VERSION ""

NS_ :

BU_: EBCM EON CAM RADAR PCM EPS VSA SCM BDY XXX EPB

BO_ 506 BRAKE_COMMAND: 8 ADAS
 SG_ COMPUTER_BRAKE : 7|10@0+ (1,0) [0|1] "" EBCM
 SG_ SET_ME_X00 : 13|5@0+ (1,0) [0|1] "" EBCM
 SG_ BRAKE_PUMP_REQUEST : 8|1@0+ (1,0) [0|1] "" EBCM
 SG_ SET_ME_X00_2 : 23|3@0+ (1,0) [0|1] "" EBCM
 SG_ CRUISE_OVERRIDE : 20|1@0+ (1,0) [0|1] "" EBCM
 SG_ SET_ME_X00_3 : 19|1@0+ (1,0) [0|1] "" EBCM
 SG_ CRUISE_FAULT_CMD : 18|1@0+ (1,0) [0|1] "" EBCM
 SG_ CRUISE_CANCEL_CMD : 17|1@0+ (1,0) [0|1] "" EBCM
 SG_ COMPUTER_BRAKE_REQUEST : 16|1@0+ (1,0) [0|1] "" EBCM
 SG_ SET_ME_1 : 31|1@0+ (1,0) [0|1] "" EBCM
 SG_ AEB_REQ_1 : 29|1@0+ (1,0) [0|1] "" XXX
 SG_ AEB_REQ_2 : 26|3@0+ (1,0) [0|7] "" XXX
 SG_ BRAKE_LIGHTS : 39|1@0+ (1,0) [0|1] "" EBCM
 SG_ CRUISE_STATES : 38|7@0+ (1,0) [0|1] "" EBCM
 SG_ CHIME : 47|3@0+ (1,0) [0|7] "" EBCM
 SG_ SET_ME_X00_4 : 44|1@0+ (1,0) [0|1] "" EBCM
 SG_ FCW : 43|2@0+ (1,0) [0|3] "" EBCM
 SG_ AEB_STATUS : 41|2@0+ (1,0) [0|3] "" XXX
 SG_ SET_ME_X00_5 : 55|8@0+ (1,0) [0|0] "" EBCM
 SG_ COUNTER : 61|2@0+ (1,0) [0|3] "" EBCM
 SG_ CHECKSUM : 59|4@0+ (1,0) [0|15] "" EBCM

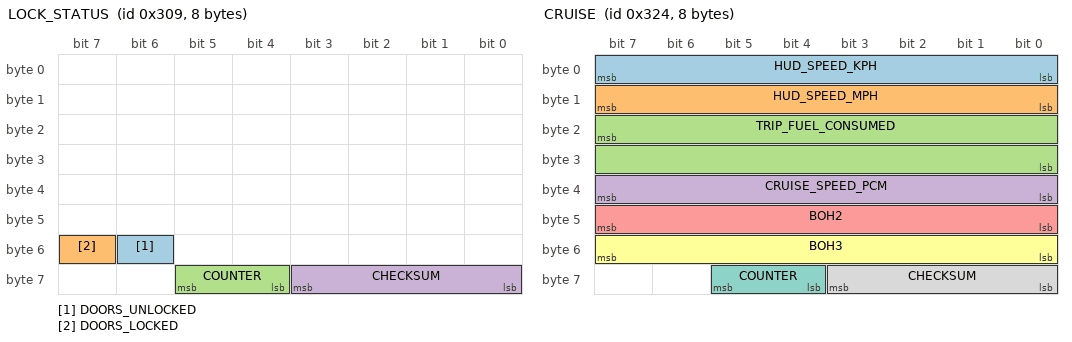
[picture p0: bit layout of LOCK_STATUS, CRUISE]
BO_ 777 LOCK_STATUS: 8 XXX
 SG_ DOORS_UNLOCKED : 54|1@0+ (1,0) [0|1] "" EON
 SG_ DOORS_LOCKED : 55|1@0+ (1,0) [0|1] "" EON
 SG_ COUNTER : 61|2@0+ (1,0) [0|3] "" EON
 SG_ CHECKSUM : 59|4@0+ (1,0) [0|3] "" EON

BO_ 780 ACC_HUD: 8 ADAS
 SG_ PCM_SPEED : 7|16@0+ (0.01,0) [0|250] "kph" BDY
 SG_ PCM_GAS : 23|8@0+ (1,0) [0|127] "" BDY
 SG_ CRUISE_SPEED : 31|8@0+ (1,0) [0|255] "" BDY
 SG_ DTC_MODE : 39|1@0+ (1,0) [0|1] "" BDY
 SG_ BOH : 38|1@0+ (1,0) [0|1] "" BDY
 SG_ ACC_PROBLEM : 37|1@0+ (1,0) [0|1] "" BDY
 SG_ FCM_OFF : 36|1@0+ (1,0) [0|1] "" BDY
 SG_ FCM_OFF_2 : 35|1@0+ (1,0) [0|1] "" BDY
 SG_ FCM_PROBLEM : 34|1@0+ (1,0) [0|1] "" BDY
 SG_ RADAR_OBSTRUCTED : 33|1@0+ (1,0) [0|1] "" BDY
 SG_ ENABLE_MINI_CAR : 32|1@0+ (1,0) [0|1] "" BDY
 SG_ HUD_DISTANCE : 47|2@0+ (1,0) [0|3] "" BDY
 SG_ HUD_LEAD : 45|2@0+ (1,0) [0|3] "" BDY
 SG_ BOH_3 : 43|1@0+ (1,0) [0|3] "" BDY
 SG_ BOH_4 : 42|1@0+ (1,0) [0|3] "" BDY
 SG_ BOH_5 : 41|1@0+ (1,0) [0|3] "" BDY
 SG_ CRUISE_CONTROL_LABEL : 40|1@0+ (1,0) [0|3] "" BDY
 SG_ SET_ME_X01_2 : 55|1@0+ (1,0) [0|1] "" BDY
 SG_ IMPERIAL_UNIT : 54|1@0+ (1,0) [0|1] "" BDY
 SG_ HUD_DISTANCE_3 : 52|1@0+ (1,0) [0|1] "" BDY
 SG_ CHIME : 51|3@0+ (1,0) [0|1] "" BDY
 SG_ SET_ME_X01 : 48|1@0+ (1,0) [0|1] "" BDY
 SG_ ICONS : 63|2@0+ (1,0) [0|1] "" BDY
 SG_ COUNTER : 61|2@0+ (1,0) [0|3] "" BDY
 SG_ CHECKSUM : 59|4@0+ (1,0) [0|3] "" BDY

BO_ 804 CRUISE: 8 PCM
 SG_ HUD_SPEED_KPH : 7|8@0+ (1,0) [0|255] "kph" EON
 SG_ HUD_SPEED_MPH : 15|8@0+ (1,0) [0|255] "mph" EON
 SG_ TRIP_FUEL_CONSUMED : 23|16@0+ (1,0) [0|255] "" EON
 SG_ CRUISE_SPEED_PCM : 39|8@0+ (1,0) [0|255] "" EON
 SG_ BOH2 : 47|8@0- (1,0) [0|255] "" EON
 SG_ BOH3 : 55|8@0+ (1,0) [0|255] "" EON
 SG_ COUNTER : 61|2@0+ (1,0) [0|3] "" EON
 SG_ CHECKSUM : 59|4@0+ (1,0) [0|3] "" EON

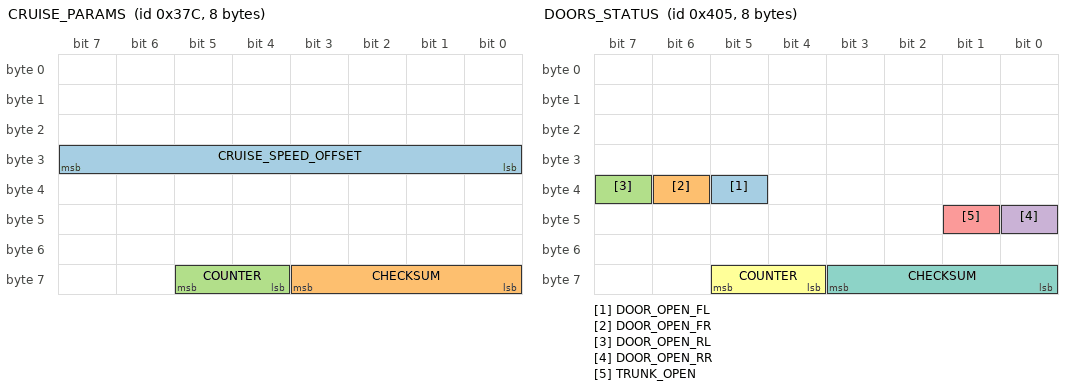
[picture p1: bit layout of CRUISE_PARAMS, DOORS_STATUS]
BO_ 892 CRUISE_PARAMS: 8 PCM
 SG_ CRUISE_SPEED_OFFSET : 31|8@0- (0.1,0) [-128|127] "kph" EON
 SG_ CHECKSUM : 59|4@0+ (1,0) [0|3] "" EON
 SG_ COUNTER : 61|2@0+ (1,0) [0|3] "" EON

BO_ 1029 DOORS_STATUS: 8 BDY
 SG_ DOOR_OPEN_FL : 37|1@0+ (1,0) [0|1] "" EON
 SG_ DOOR_OPEN_FR : 38|1@0+ (1,0) [0|1] "" EON
 SG_ DOOR_OPEN_RL : 39|1@0+ (1,0) [0|1] "" EON
 SG_ DOOR_OPEN_RR : 40|1@0+ (1,0) [0|1] "" EON
 SG_ TRUNK_OPEN : 41|1@0+ (1,0) [0|1] "" EON
 SG_ COUNTER : 61|2@0+ (1,0) [0|3] "" EON
 SG_ CHECKSUM : 59|4@0+ (1,0) [0|3] "" EON
